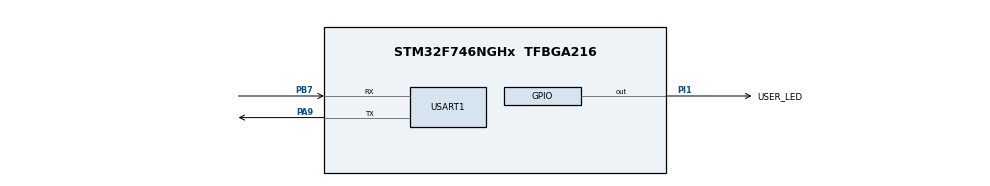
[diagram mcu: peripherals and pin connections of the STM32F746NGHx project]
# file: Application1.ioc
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CORTEX_M7.default_mode_Activation=1
Mcu.Family=STM32F7
Mcu.Name=STM32F746NGHx
Mcu.Package=TFBGA216
NVIC.PriorityGroup=NVIC_PRIORITYGROUP_4
PA13.Signal=SYS_JTMS-SWDIO
PA14.Signal=SYS_JTCK-SWCLK
PA9.Mode=Asynchronous
PA9.Signal=USART1_TX
PB7.Mode=Asynchronous
PB7.Signal=USART1_RX
PI1.GPIO_Label=USER_LED
PI1.Signal=GPIO_Output
ProjectManager.HeapSize=0x200
ProjectManager.StackSize=0x400
ProjectManager.TargetToolchain=STM32CubeIDE
RCC.HSE_VALUE=25000000
RCC.HSI_VALUE=16000000
RCC.LSE_VALUE=32768
RCC.USBFreq_Value=96000000
RCC.VCOOutputFreq_Value=192000000
USART1.VirtualMode-Asynchronous=VM_ASYNC
VP_RTC_VS_RTC_Activate.Mode=RTC_Enabled
board=custom

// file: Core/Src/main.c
/* USER CODE BEGIN Header */
/**
  ******************************************************************************
  * @file           : main.c
  * @brief          : Main program body
  ******************************************************************************
  * @attention
  *
  * Copyright (c) 2025 STMicroelectronics.
  * All rights reserved.
  *
  * This software is licensed under terms that can be found in the LICENSE file
  * in the root directory of this software component.
  * If no LICENSE file comes with this software, it is provided AS-IS.
  *
  ******************************************************************************
  */
/* USER CODE END Header */
#include "main.h"

/* USER CODE BEGIN Includes */
#include <stdio.h>
/* USER CODE END Includes */

RTC_HandleTypeDef hrtc;

UART_HandleTypeDef huart1;

void SystemClock_Config(void);
static void MPU_Config(void);
static void MX_GPIO_Init(void);
static void MX_RTC_Init(void);
static void MX_USART1_UART_Init(void);

int main(void)
{

  /* MPU Configuration--------------------------------------------------------*/
  //MPU_Config();

  /* MCU Configuration--------------------------------------------------------*/

  /* Reset of all peripherals, Initializes the Flash interface and the Systick. */
  HAL_Init();

  /* Configure the system clock */
  SystemClock_Config();

  /* USER CODE BEGIN SysInit */
  __enable_irq();
  /* USER CODE END SysInit */

  /* Initialize all configured peripherals */
  MX_GPIO_Init();
  MX_RTC_Init();
  MX_USART1_UART_Init();
  /* USER CODE BEGIN 2 */
  uint32_t current_sp = __get_MSP();
  printf("Application1'den selam\r\n");
  printf("Current Stack Pointer (MSP): 0x%08lX\r\n", current_sp);

  /* USER CODE END 2 */

  /* Infinite loop */
  /* USER CODE BEGIN WHILE */
  while (1)
  {
	  HAL_GPIO_TogglePin(GPIOI, USER_LED_Pin);
	  HAL_Delay(200);
    /* USER CODE END WHILE */

  }
}

void SystemClock_Config(void)
{
  RCC_OscInitTypeDef RCC_OscInitStruct = {0};
  RCC_ClkInitTypeDef RCC_ClkInitStruct = {0};

  /** Configure the main internal regulator output voltage
  */
  __HAL_RCC_PWR_CLK_ENABLE();
  __HAL_PWR_VOLTAGESCALING_CONFIG(PWR_REGULATOR_VOLTAGE_SCALE3);

  /** Initializes the RCC Oscillators according to the specified parameters
  * in the RCC_OscInitTypeDef structure.
  */
  RCC_OscInitStruct.OscillatorType = RCC_OSCILLATORTYPE_HSI|RCC_OSCILLATORTYPE_LSI;
  RCC_OscInitStruct.HSIState = RCC_HSI_ON;
  RCC_OscInitStruct.HSICalibrationValue = RCC_HSICALIBRATION_DEFAULT;
  RCC_OscInitStruct.LSIState = RCC_LSI_ON;
  RCC_OscInitStruct.PLL.PLLState = RCC_PLL_NONE;
  if (HAL_RCC_OscConfig(&RCC_OscInitStruct) != HAL_OK)
  {
    Error_Handler();
  }

  /** Initializes the CPU, AHB and APB buses clocks
  */
  RCC_ClkInitStruct.ClockType = RCC_CLOCKTYPE_HCLK|RCC_CLOCKTYPE_SYSCLK
                              |RCC_CLOCKTYPE_PCLK1|RCC_CLOCKTYPE_PCLK2;
  RCC_ClkInitStruct.SYSCLKSource = RCC_SYSCLKSOURCE_HSI;
  RCC_ClkInitStruct.AHBCLKDivider = RCC_SYSCLK_DIV1;
  RCC_ClkInitStruct.APB1CLKDivider = RCC_HCLK_DIV1;
  RCC_ClkInitStruct.APB2CLKDivider = RCC_HCLK_DIV1;

  if (HAL_RCC_ClockConfig(&RCC_ClkInitStruct, FLASH_LATENCY_0) != HAL_OK)
  {
    Error_Handler();
  }
}

static void MX_RTC_Init(void)
{

  /** Initialize RTC Only
  */
  hrtc.Instance = RTC;
  hrtc.Init.HourFormat = RTC_HOURFORMAT_24;
  hrtc.Init.AsynchPrediv = 127;
  hrtc.Init.SynchPrediv = 255;
  hrtc.Init.OutPut = RTC_OUTPUT_DISABLE;
  hrtc.Init.OutPutPolarity = RTC_OUTPUT_POLARITY_HIGH;
  hrtc.Init.OutPutType = RTC_OUTPUT_TYPE_OPENDRAIN;
  if (HAL_RTC_Init(&hrtc) != HAL_OK)
  {
    Error_Handler();
  }

}

static void MX_USART1_UART_Init(void)
{

  huart1.Instance = USART1;
  huart1.Init.BaudRate = 115200;
  huart1.Init.WordLength = UART_WORDLENGTH_8B;
  huart1.Init.StopBits = UART_STOPBITS_1;
  huart1.Init.Parity = UART_PARITY_NONE;
  huart1.Init.Mode = UART_MODE_TX_RX;
  huart1.Init.HwFlowCtl = UART_HWCONTROL_NONE;
  huart1.Init.OverSampling = UART_OVERSAMPLING_16;
  huart1.Init.OneBitSampling = UART_ONE_BIT_SAMPLE_DISABLE;
  huart1.AdvancedInit.AdvFeatureInit = UART_ADVFEATURE_NO_INIT;
  if (HAL_UART_Init(&huart1) != HAL_OK)
  {
    Error_Handler();
  }

}

static void MX_GPIO_Init(void)
{
  GPIO_InitTypeDef GPIO_InitStruct = {0};

  /* GPIO Ports Clock Enable */
  __HAL_RCC_GPIOA_CLK_ENABLE();
  __HAL_RCC_GPIOB_CLK_ENABLE();
  __HAL_RCC_GPIOI_CLK_ENABLE();

  /*Configure GPIO pin Output Level */
  HAL_GPIO_WritePin(USER_LED_GPIO_Port, USER_LED_Pin, GPIO_PIN_RESET);

  /*Configure GPIO pin : USER_LED_Pin */
  GPIO_InitStruct.Pin = USER_LED_Pin;
  GPIO_InitStruct.Mode = GPIO_MODE_OUTPUT_PP;
  GPIO_InitStruct.Pull = GPIO_NOPULL;
  GPIO_InitStruct.Speed = GPIO_SPEED_FREQ_LOW;
  HAL_GPIO_Init(USER_LED_GPIO_Port, &GPIO_InitStruct);

}

/* USER CODE BEGIN 4 */
/**
 * @brief Redirects standard output to USART1 using polling.
 *
 * Sends a buffer over USART1 and inserts '\r' before '\n'
 * for proper terminal formatting.
 *
 * @param file File descriptor (unused)
 * @param ptr  Data buffer to send
 * @param len  Number of bytes to send
 * @return Number of bytes written
 *
 * @author Omert2004
 */
int _write(int file, char *ptr, int len)
{
    for (int i = 0; i < len; i++)
    {
        // Check for new line character to fix terminal formatting
        if (ptr[i] == '\n')
        {
            while (!(USART1->ISR & USART_ISR_TXE));
            USART1->TDR = '\r'; // Send Carriage Return
        }
        // 1. Wait for the Transmit Data Register Empty (TXE) flag
        while (!(USART1->ISR & USART_ISR_TXE));

        // 2. Write the character to the Transmit Data Register (TDR)
        USART1->TDR = (uint8_t)ptr[i];
    }
    return len;
}

/* USER CODE END 4 */

 /* MPU Configuration */

void MPU_Config(void)
{
  MPU_Region_InitTypeDef MPU_InitStruct = {0};

  /* Disables the MPU */
  HAL_MPU_Disable();

  /** Initializes and configures the Region and the memory to be protected
  */
  MPU_InitStruct.Enable = MPU_REGION_ENABLE;
  MPU_InitStruct.Number = MPU_REGION_NUMBER0;
  MPU_InitStruct.BaseAddress = 0x0;
  MPU_InitStruct.Size = MPU_REGION_SIZE_4GB;
  MPU_InitStruct.SubRegionDisable = 0x87;
  MPU_InitStruct.TypeExtField = MPU_TEX_LEVEL0;
  MPU_InitStruct.AccessPermission = MPU_REGION_NO_ACCESS;
  MPU_InitStruct.DisableExec = MPU_INSTRUCTION_ACCESS_DISABLE;
  MPU_InitStruct.IsShareable = MPU_ACCESS_SHAREABLE;
  MPU_InitStruct.IsCacheable = MPU_ACCESS_NOT_CACHEABLE;
  MPU_InitStruct.IsBufferable = MPU_ACCESS_NOT_BUFFERABLE;

  HAL_MPU_ConfigRegion(&MPU_InitStruct);
  /* Enables the MPU */
  HAL_MPU_Enable(MPU_PRIVILEGED_DEFAULT);

}

void Error_Handler(void)
{
  __disable_irq();
  while (1)
  {
  }
}
